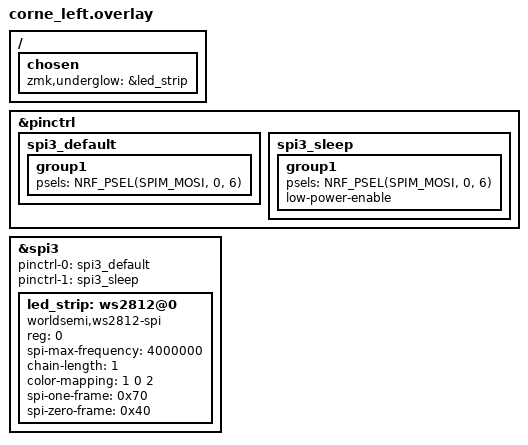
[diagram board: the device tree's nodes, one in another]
/ {
    chosen {
        zmk,underglow = &led_strip;
    };
};

&pinctrl {
    spi3_default: spi3_default {
        group1 {
            psels = <NRF_PSEL(SPIM_MOSI, 0, 6)>;
        };
    };

    spi3_sleep: spi3_sleep {
        group1 {
            psels = <NRF_PSEL(SPIM_MOSI, 0, 6)>;
            low-power-enable;
        };
    };
};

&spi3 {
    status = "okay";
    pinctrl-0 = <&spi3_default>;
    pinctrl-1 = <&spi3_sleep>;
    pinctrl-names = "default", "sleep";

    led_strip: ws2812@0 {
        compatible = "worldsemi,ws2812-spi";
        reg = <0>;
        spi-max-frequency = <4000000>;
        chain-length = <1>;

        /* Обычно SK6812/WS2812 — GRB */
        color-mapping = <1 0 2>;
        spi-one-frame = <0x70>;
        spi-zero-frame = <0x40>;
    };
};
